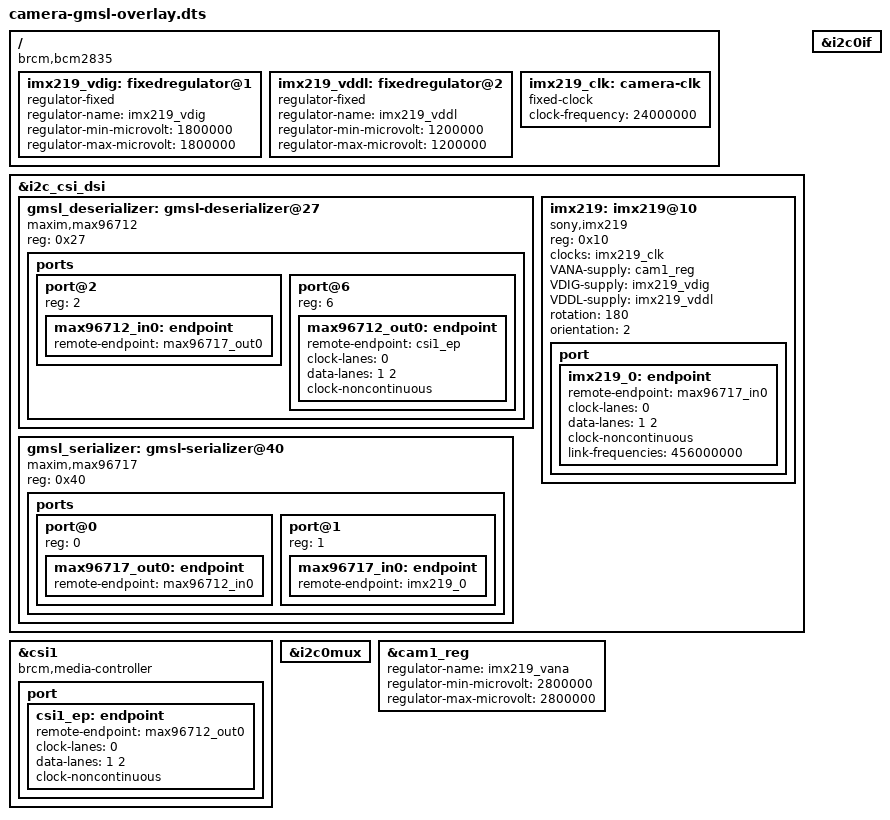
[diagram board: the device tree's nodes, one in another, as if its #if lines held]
// SPDX-License-Identifier: GPL-2.0-only

/dts-v1/;
/plugin/;

#include <dt-bindings/gpio/gpio.h>

// #define GMSL_DESERIALIZER
// #define GMSL_SERIALIZER
#define GMSL_CAMERA

#if defined(GMSL_CAMERA)
// camera only
#elif defined(GMSL_DESERIALIZER)
// deserializer only
#elif defined(GMSL_DESERIALIZER) && defined(GMSL_SERIALIZER) && defined(GMSL_SERIALIZER)
// full setup
#else
#error
#endif

/ {
	compatible = "brcm,bcm2835";

	fragment@0 {
		target = <&i2c_csi_dsi>;
		__overlay__ {
			#address-cells = <1>;
			#size-cells = <0>;
			status = "okay";

#if defined(GMSL_DESERIALIZER)
			gmsl_deserializer: gmsl-deserializer@27 {
				compatible = "maxim,max96712";
				reg = <0x27>;

				ports {
					#address-cells = <1>;
					#size-cells = <0>;

#if defined(GMSL_SERIALIZER)
					port@2 {
						reg = <2>;

						max96712_in0: endpoint {
							remote-endpoint = <&max96717_out0>;
						};
					};
#endif

					port@6 {
						reg = <6>;
						max96712_out0: endpoint {
							remote-endpoint = <&csi1_ep>;
							clock-lanes = <0>;
							data-lanes = <1 2>;
							clock-noncontinuous;
						};
					};
				};
			};
#endif

#ifdef GMSL_SERIALIZER
			gmsl_serializer: gmsl-serializer@40 {
				compatible = "maxim,max96717";
				reg = <0x40>;

				ports {
					#address-cells = <1>;
					#size-cells = <0>;

					port@0 {
						reg = <0>;
						max96717_out0: endpoint {
							remote-endpoint = <&max96712_in0>;
						};
					};

					port@1 {
						reg = <1>;
						max96717_in0: endpoint {
							remote-endpoint = <&imx219_0>;
						};
					};
				};
			};
#endif

#if defined(GMSL_CAMERA)
			imx219: imx219@10 {
				compatible = "sony,imx219";
				reg = <0x10>;
				status = "okay";

				clocks = <&imx219_clk>;
				clock-names = "xclk";

				VANA-supply = <&cam1_reg>;	/* 2.8v */
				VDIG-supply = <&imx219_vdig>;	/* 1.8v */
				VDDL-supply = <&imx219_vddl>;	/* 1.2v */

				rotation = <180>;
				orientation = <2>;

				port {
					imx219_0: endpoint {
#if defined(GMSL_SERIALIZER)
						remote-endpoint = <&max96717_in0>;
#elif defined(GMSL_CAMERA)
						remote-endpoint = <&csi1_ep>;
#else
#error
#endif
						clock-lanes = <0>;
						data-lanes = <1 2>;
						clock-noncontinuous;
						link-frequencies =
							/bits/ 64 <456000000>;
					};
				};
			};
		};
	};
#endif

	fragment@1 {
		target = <&csi1>;
		__overlay__ {
			status = "okay";

			brcm,media-controller;

			port {
				csi1_ep: endpoint {
#if defined(GMSL_DESERIALIZER)
					remote-endpoint = <&max96712_out0>;
#elif defined(GMSL_CAMERA)
					remote-endpoint = <&imx219_0>;
#else
#error
#endif
					clock-lanes = <0>;
					data-lanes = <1 2>;
					clock-noncontinuous;
				};
			};
		};
	};

	fragment@2 {
		target = <&i2c0if>;
		__overlay__ {
			status = "okay";
		};
	};

	fragment@3 {
		target = <&i2c0mux>;
		__overlay__ {
			status = "okay";
		};
	};

#if defined(GMSL_CAMERA)
	fragment@4 {
		target-path = "/";

		__overlay__ {
			imx219_vdig: fixedregulator@1 {
				compatible = "regulator-fixed";
				regulator-name = "imx219_vdig";
				regulator-min-microvolt = <1800000>;
				regulator-max-microvolt = <1800000>;
			};

			imx219_vddl: fixedregulator@2 {
				compatible = "regulator-fixed";
				regulator-name = "imx219_vddl";
				regulator-min-microvolt = <1200000>;
				regulator-max-microvolt = <1200000>;
			};

			imx219_clk: camera-clk {
				compatible = "fixed-clock";
				#clock-cells = <0>;
				clock-frequency = <24000000>;
			};
		};
	};

	fragment@5 {
		target = <&cam1_reg>;

		__overlay__ {
			status = "okay";
			regulator-name = "imx219_vana";
			regulator-min-microvolt = <2800000>;
			regulator-max-microvolt = <2800000>;
		};
	};
#endif

};
